# STM32WL5x_CM0P register map
File version: 1.9
CPU: CM0 r0p1, little endian, MPU, no FPU, 4 interrupt priority bits
Registers are 32-bit, read-write, reset 0x0 unless marked. A register's access mark holds for its fields unless they carry their own. Offsets are from the block's base; [hi:lo] are bit positions; {n}, {i} and the like mark numbered series; 'fields as' and 'values as' point back to an identical list.

## DMA1 — Direct memory access controller
Base 0x40020000
Same registers: DMA2 0x40020400
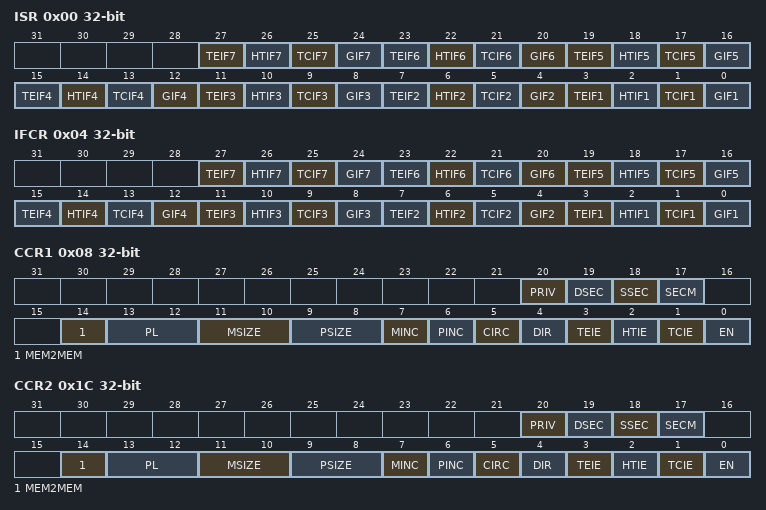
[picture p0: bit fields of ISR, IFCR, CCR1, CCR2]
0x00 ISR ro — interrupt status register
  [4n-1] TEIF{n} (n=1..7) — transfer error (TE) flag for channel {n}
  [4n-2] HTIF{n} (n=1..7) — half transfer (HT) flag for channel {n}
  [4n-3] TCIF{n} (n=1..7) — transfer complete (TC) flag for channel {n}
  [4n-4] GIF{n} (n=1..7) — global interrupt flag for channel {n}
0x04 IFCR wo — interrupt flag clear register
  [4n-1] TEIF{n} (n=1..7) — transfer error flag clear for channel {n}
  [4n-2] HTIF{n} (n=1..7) — half transfer flag clear for channel {n}
  [4n-3] TCIF{n} (n=1..7) — transfer complete flag clear for channel {n}
  [4n-4] GIF{n} (n=1..7) — global interrupt flag clear for channel {n}
0x08 CCR1 — channel x configuration register
  [20] PRIV — rivileged mode
  [19] DSEC — ecurity of the DMA transfer to the destination
  [18] SSEC — ecurity of the DMA transfer from the source
  [17] SECM — ecure mode
  [14] MEM2MEM — memory-to-memory mode
  [13:12] PL — priority level
  [11:10] MSIZE — memory size
  [9:8] PSIZE — peripheral size
  [7] MINC — memory increment mode
  [6] PINC — peripheral increment mode
  [5] CIRC — circular mode
  [4] DIR — data transfer direction
  [3] TEIE — transfer error interrupt enable
  [2] HTIE — half transfer interrupt enable
  [1] TCIE — transfer complete interrupt enable
  [0] EN — channel enable
0x0C CNDTR1 — channel x number of data to transfer register
  [17:0] NDT — number of data to transfer (0 to 218 - 1)
0x10 CPAR1 — channel x peripheral address register
  [31:0] PA — peripheral address
{0x0+0x14*i} CMAR{i} (i=1..7) — channel x memory address register
  [31:0] MA — peripheral address
0x1C CCR2 — channel x configuration register
  fields as CCR1
0x20 CNDTR2 — channel x number of data to transfer register
  [17:0] NDT — number of data to transfer (0 to 218 - 1)
0x24 CPAR2 — channel x peripheral address register
  [31:0] PA — peripheral address
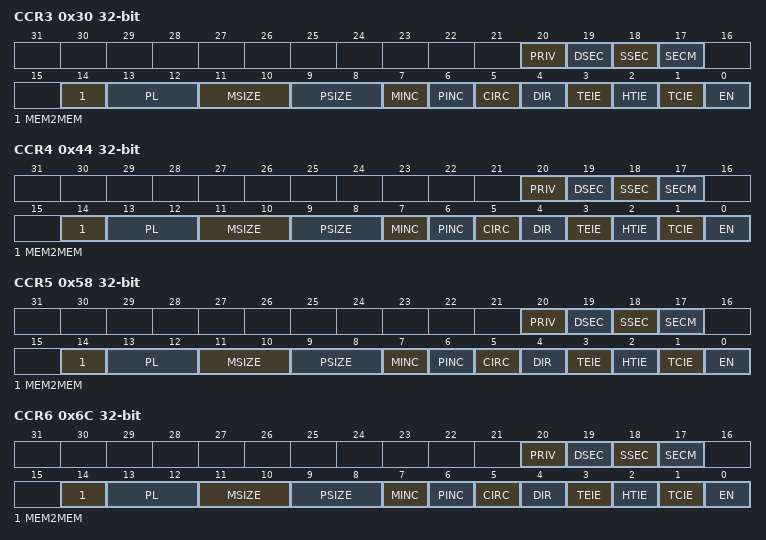
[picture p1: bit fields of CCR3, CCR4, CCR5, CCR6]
0x30 CCR3 — channel x configuration register
  fields as CCR1
0x34 CNDTR3 — channel x number of data to transfer register
  [17:0] NDT — number of data to transfer (0 to 218 - 1)
0x38 CPAR3 — channel x peripheral address register
  [31:0] PA — peripheral address
0x44 CCR4 — channel x configuration register
  fields as CCR1
0x48 CNDTR4 — channel x number of data to transfer register
  [17:0] NDT — number of data to transfer (0 to 218 - 1)
0x4C CPAR4 — channel x peripheral address register
  [31:0] PA — peripheral address
0x58 CCR5 — channel x configuration register
  fields as CCR1
0x5C CNDTR5 — channel x number of data to transfer register
  [17:0] NDT — number of data to transfer (0 to 218 - 1)
0x60 CPAR5 — channel x peripheral address register
  [31:0] PA — peripheral address
0x6C CCR6 — channel x configuration register
  fields as CCR1
0x70 CNDTR6 — channel x number of data to transfer register
  [17:0] NDT — number of data to transfer (0 to 218 - 1)
0x74 CPAR6 — channel x peripheral address register
  [31:0] PA — peripheral address
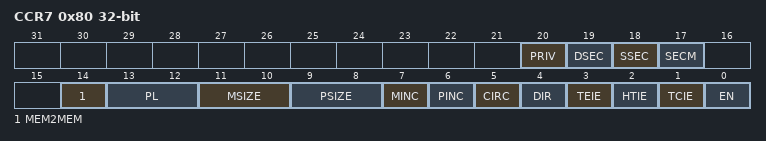
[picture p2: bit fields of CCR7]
0x80 CCR7 — channel x configuration register
  fields as CCR1
0x84 CNDTR7 — channel x number of data to transfer register
  [17:0] NDT — number of data to transfer (0 to 218 - 1)
0x88 CPAR7 — channel x peripheral address register
  [31:0] PA — peripheral address

## DMAMUX — DMA request multiplexer
Base 0x40020800
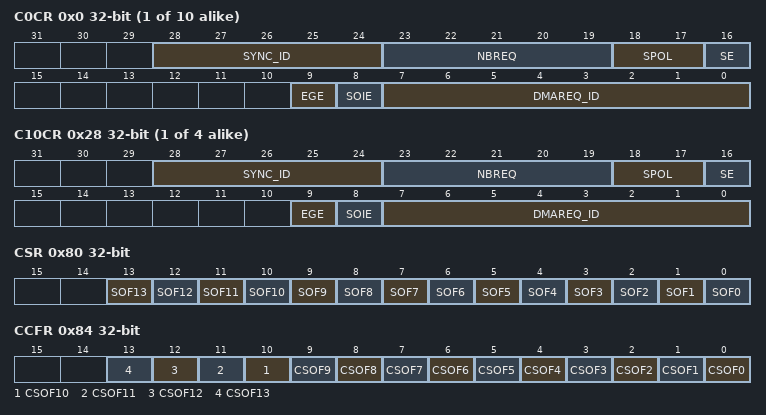
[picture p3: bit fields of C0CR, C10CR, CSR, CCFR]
{0x0+4i} C{i}CR (i=0..9) — request line multiplexer channel x configuration register
  [28:24] SYNC_ID — Synchronization identification
  [23:19] NBREQ — Number of DMA requests minus 1 to forward
  [18:17] SPOL — Synchronization polarity
  [16] SE — Synchronization enable
  [9] EGE — Event generation enable
  [8] SOIE — Synchronization overrun interrupt enable
  [7:0] DMAREQ_ID — DMA request identification
{0x0+4i} C{i}CR (i=10..13)
  [28:24] SYNC_ID, [23:19] NBREQ, [18:17] SPOL, [16] SE, [9] EGE, [8] SOIE, [7:0] DMAREQ_ID
0x80 CSR ro — request line multiplexer interrupt channel status register
  [13] SOF13 — Synchronization overrun event flag
  [n] SOF{n} (n=0..12)
0x84 CCFR wo — request line multiplexer interrupt channel clear flag register
  [n] CSOF{n} (n=0..13)
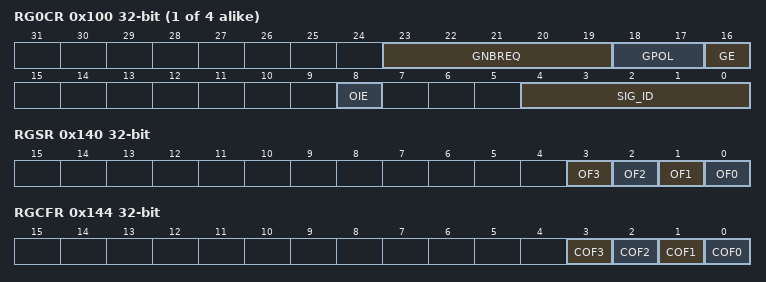
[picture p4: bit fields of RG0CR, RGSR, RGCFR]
{0x100+4i} RG{i}CR (i=0..3) — request generator channel x configuration register
  [23:19] GNBREQ — Number of DMA requests to be generated (minus 1)
  [18:17] GPOL — DMA request generator trigger polarity
  [16] GE — DMA request generator channel x enable
  [8] OIE — Trigger overrun interrupt enable
  [4:0] SIG_ID — Signal identification
0x140 RGSR ro — request generator interrupt status register
  [3] OF3 — Trigger overrun event flag
  [2] OF2
  [1] OF1
  [0] OF0
0x144 RGCFR wo — request generator interrupt clear flag register
  [3] COF3 — Clear trigger overrun event flag
  [2] COF2
  [1] COF1
  [0] COF0
